# nrf5340 register map
Vendor: Nordic Semiconductor; Series: nrf53; File version: 1
CPU: CM33 r0p2, little endian, MPU, FPU, 3 interrupt priority bits
Registers are 32-bit, read-write, reset 0x0 unless marked. A register's access mark holds for its fields unless they carry their own. Offsets are from the block's base; [hi:lo] are bit positions; lines under a group give offsets from that group; {n}, {i} and the like mark numbered series; 'fields as' and 'values as' point back to an identical list.

## CTRLAP_NS — Control access port 0
Base 0x40006000
Same registers: CTRLAP_S 0x50006000
0x400 CTRLDAP2COREDATA ro — Data sent from the Debugger to the Core
  [31:0] DATA — General Data
0x404 CTRLDAP2CORESTATUS ro — Status to indicate if Data sent from the Debugger to the Core has been read
  [0] STATUS — Status of data in CTRLDAP2COREDATA register
    0=No data pending in CTRLDAP2COREDATA; 1=Data pending in CTRLDAP2COREDATA
0x480 CORE2CTRLDAPDATA — Data sent from the Core to the Debugger
  [31:0] DATA — General Data
0x484 CORE2CTRLDAPSTATUS ro — Status to indicate if Data sent from the Core to the Debugger status has been read
  [0] STATUS — Status of data in CORE2CTRLDAPDATA register
    values as CTRLDAP2CORESTATUS.STATUS
0x500 CPURETURNFIELD_LOCK wo — Lock Mail Box erase all mechanism
  [0] LOCK — Enable or disable the erase all mechanism for return field case. A write once register.
    0=Enabled (Eraseall for return field can be issued); 1=Disabled (Eraseall for return field is locked)
0x504 CPURETURNFIELD wo — Mail box erase all control register. A write once register.
  [31:0] STATUS — Random value to generate a eraseall for return field case.

## PAMLI_NS — Peripheral AHB Multi-Layer Interface 0
Base 0x40007000
Same registers: PAMLI_S 0x50007000
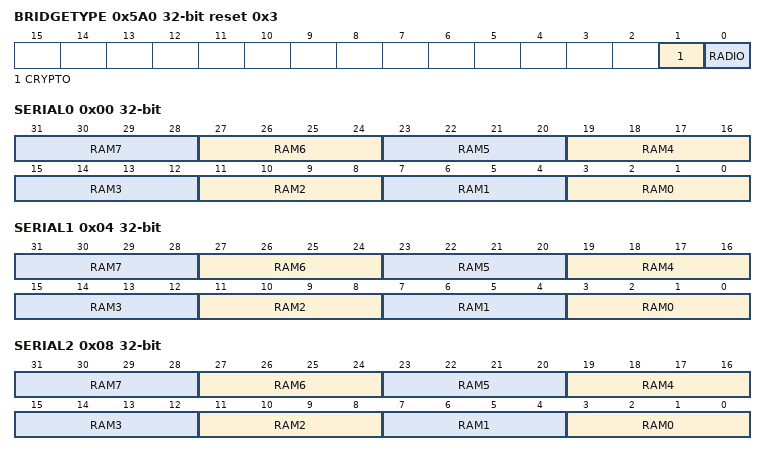
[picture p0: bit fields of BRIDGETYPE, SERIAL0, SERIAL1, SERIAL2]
0x5A0 BRIDGETYPE reset 0x3 — Select AHB2AHB Sync Bridge Type
  [1] CRYPTO — Select bridge type for CCM, ECB, AAR
    0=Default (Select standard ARM bridge); 1=Nordic (Select Nordic bridge)
  [0] RADIO — Select bridge type for RADIO
    values as CRYPTO
0xE00 RAMPRI group — RAM configurable priority configuration structure
  0x00 SERIAL0 — AHB bus master priority register for SPIM0, SPIS0, TWIM0, TWIS0 and UARTE0
    [all] fields
      {v}=Pri{v} (Priority {v}) (v=0..7)
    [4n+3:4n] RAM{n} (n=0..7) — Priority register for RAM AHB slave {n}
  0x04 SERIAL1 — AHB bus master priority register for SPIM1, SPIS1, TWIM1, TWIS1 and UARTE1
    fields as RAMPRI.SERIAL0
  0x08 SERIAL2 — AHB bus master priority register for SPIM2
    fields as RAMPRI.SERIAL0
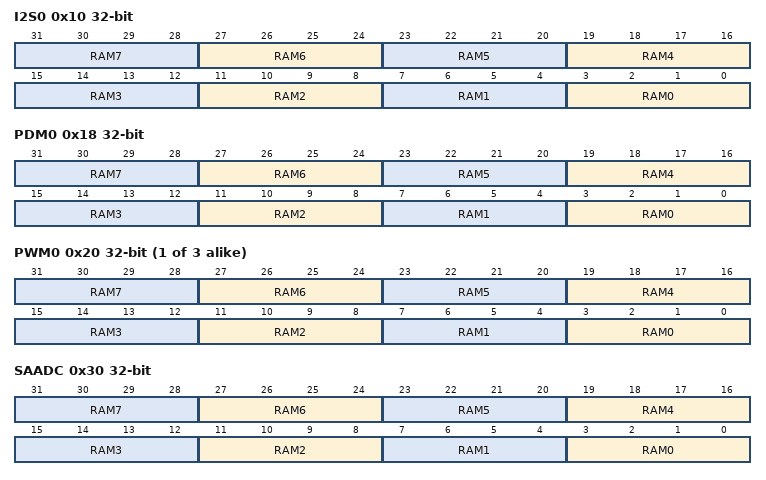
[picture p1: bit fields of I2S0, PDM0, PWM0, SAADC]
  0x10 I2S0 — AHB bus master priority register for I2S0
    fields as RAMPRI.SERIAL0
  0x18 PDM0 — AHB bus master priority register for PDM0
    fields as RAMPRI.SERIAL0
  {0x20+4j} PWM{j} (j=0..2) — AHB bus master priority register for PWM{j}
    fields as RAMPRI.SERIAL0
  0x30 SAADC — AHB bus master priority register for SAADC
    fields as RAMPRI.SERIAL0
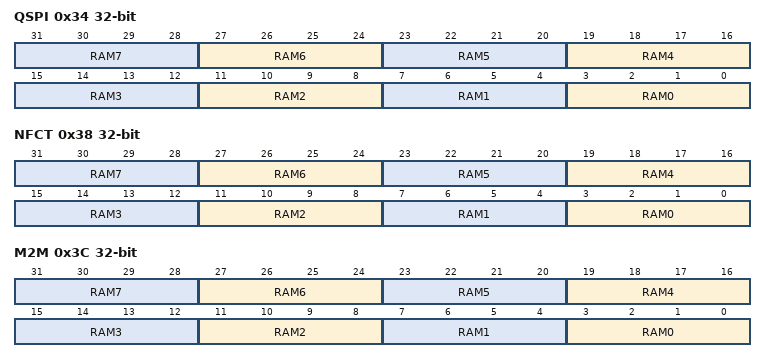
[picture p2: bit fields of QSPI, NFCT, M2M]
  0x34 QSPI — AHB bus master priority register for QSPI
    fields as RAMPRI.SERIAL0
  0x38 NFCT — AHB bus master priority register for NFCT
    fields as RAMPRI.SERIAL0
  0x3C M2M — AHB bus master priority register for M2M input and output channels
    fields as RAMPRI.SERIAL0

## DPPIC_NS — Distributed Programmable Peripheral Interconnect Controller 0
Base 0x40017000
Same registers: DPPIC_S 0x50017000
{0x0+8i} TASKS_CHG[{i}] (i=0..5) group — Channel group tasks
  0x00 EN wo — Description cluster: Enable channel group n
    [0] EN — Enable channel group n
      1=Trigger task
  0x04 DIS wo — Description cluster: Disable channel group n
    [0] DIS — Disable channel group n
      1=Trigger task
{0x80+8i} SUBSCRIBE_CHG[{i}] (i=0..5) group — Subscribe configuration for tasks
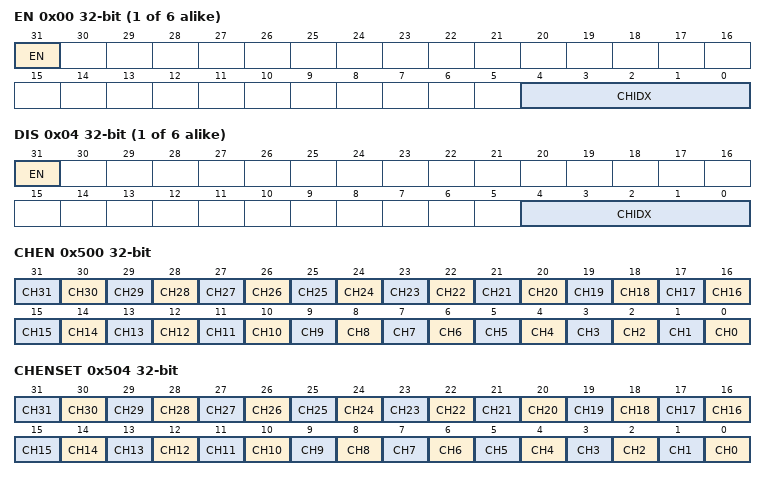
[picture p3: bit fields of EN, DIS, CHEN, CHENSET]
  0x00 EN — Description cluster: Subscribe configuration for task CHG[n].EN
    [31] EN
      0=Disabled (Disable subscription); 1=Enabled (Enable subscription)
    [4:0] CHIDX — Channel that task CHG[n].EN will subscribe to
  0x04 DIS — Description cluster: Subscribe configuration for task CHG[n].DIS
    [31] EN
      values as SUBSCRIBE_CHG[0].EN.EN
    [4:0] CHIDX — Channel that task CHG[n].DIS will subscribe to
0x500 CHEN — Channel enable register
  [all] fields
    0=Disabled (Disable channel); 1=Enabled (Enable channel)
  [n] CH{n} (n=0..31) — Enable or disable channel {n}
0x504 CHENSET write-1-sets — Channel enable set register
  [all] fields
    on read: 0=Disabled (Read: channel disabled); 1=Enabled (Read: channel enabled) | on write: 1=Set (Write: Enable channel)
  [n] CH{n} (n=0..31) — Channel {n} enable set register. Writing '0' has no effect
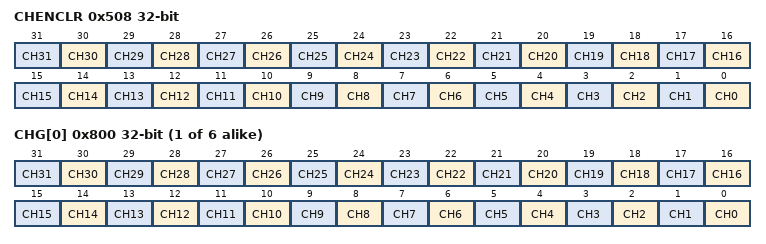
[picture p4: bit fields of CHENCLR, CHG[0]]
0x508 CHENCLR write-1-clears — Channel enable clear register
  [all] fields
    on read: 0=Disabled (Read: channel disabled); 1=Enabled (Read: channel enabled) | on write: 1=Clear (Write: disable channel)
  [n] CH{n} (n=0..31) — Channel {n} enable clear register. Writing '0' has no effect
{0x800+4i} CHG[{i}] (i=0..5) — Description collection: Channel group n Note: Writes to this register is ignored if either SUBSCRIBE_CHG[n].EN/DIS are enabled.
  [all] fields
    0=Excluded; 1=Included
  [n] CH{n} (n=0..31) — Include or exclude channel {n}
